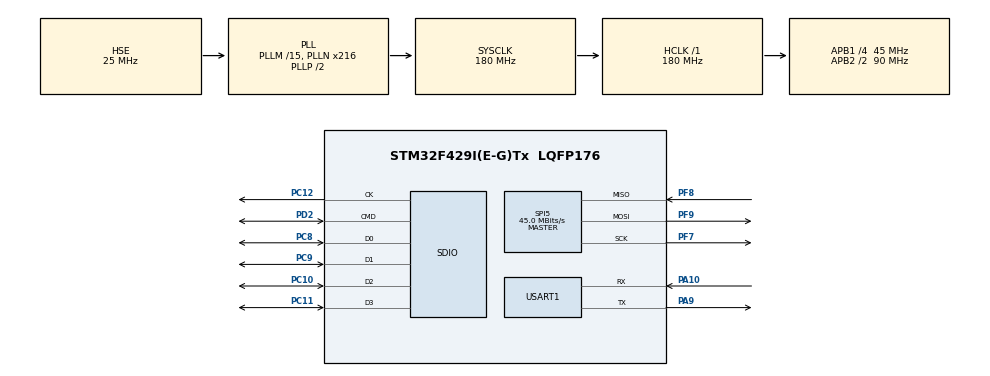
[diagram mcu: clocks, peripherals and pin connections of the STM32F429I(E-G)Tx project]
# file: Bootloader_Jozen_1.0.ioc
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Dma.Request0=SDIO_RX
Dma.Request1=SDIO_TX
Dma.SDIO_RX.0.Direction=DMA_PERIPH_TO_MEMORY
Dma.SDIO_RX.0.FIFOMode=DMA_FIFOMODE_ENABLE
Dma.SDIO_RX.0.FIFOThreshold=DMA_FIFO_THRESHOLD_FULL
Dma.SDIO_RX.0.Instance=DMA2_Stream3
Dma.SDIO_RX.0.MemBurst=DMA_MBURST_INC4
Dma.SDIO_RX.0.MemDataAlignment=DMA_MDATAALIGN_WORD
Dma.SDIO_RX.0.MemInc=DMA_MINC_ENABLE
Dma.SDIO_RX.0.Mode=DMA_PFCTRL
Dma.SDIO_RX.0.PeriphBurst=DMA_PBURST_INC4
Dma.SDIO_RX.0.PeriphDataAlignment=DMA_PDATAALIGN_WORD
Dma.SDIO_RX.0.PeriphInc=DMA_PINC_DISABLE
Dma.SDIO_RX.0.Priority=DMA_PRIORITY_LOW
Dma.SDIO_TX.1.Direction=DMA_MEMORY_TO_PERIPH
Dma.SDIO_TX.1.FIFOMode=DMA_FIFOMODE_ENABLE
Dma.SDIO_TX.1.FIFOThreshold=DMA_FIFO_THRESHOLD_FULL
Dma.SDIO_TX.1.Instance=DMA2_Stream6
Dma.SDIO_TX.1.MemBurst=DMA_MBURST_INC4
Dma.SDIO_TX.1.MemDataAlignment=DMA_MDATAALIGN_WORD
Dma.SDIO_TX.1.MemInc=DMA_MINC_ENABLE
Dma.SDIO_TX.1.Mode=DMA_PFCTRL
Dma.SDIO_TX.1.PeriphBurst=DMA_PBURST_INC4
Dma.SDIO_TX.1.PeriphDataAlignment=DMA_PDATAALIGN_WORD
Dma.SDIO_TX.1.PeriphInc=DMA_PINC_DISABLE
Dma.SDIO_TX.1.Priority=DMA_PRIORITY_LOW
Mcu.Family=STM32F4
Mcu.Name=STM32F429I(E-G)Tx
Mcu.Package=LQFP176
NVIC.DMA2_Stream3_IRQn=true\:0\:0\:false\:false\:true\:false\:true
NVIC.DMA2_Stream6_IRQn=true\:0\:0\:false\:false\:true\:false\:true
NVIC.PriorityGroup=NVIC_PRIORITYGROUP_4
NVIC.SDIO_IRQn=true\:0\:0\:false\:false\:true\:true\:true
NVIC.USART1_IRQn=true\:0\:0\:false\:false\:true\:true\:true
PA10.Mode=Asynchronous
PA10.Signal=USART1_RX
PA13.Mode=Serial_Wire
PA13.Signal=SYS_JTMS-SWDIO
PA14.Mode=Serial_Wire
PA14.Signal=SYS_JTCK-SWCLK
PA9.Mode=Asynchronous
PA9.Signal=USART1_TX
PC10.Mode=SD_4_bits_Wide_bus
PC10.Signal=SDIO_D2
PC11.Mode=SD_4_bits_Wide_bus
PC11.Signal=SDIO_D3
PC12.Mode=SD_4_bits_Wide_bus
PC12.Signal=SDIO_CK
PC8.Mode=SD_4_bits_Wide_bus
PC8.Signal=SDIO_D0
PC9.Mode=SD_4_bits_Wide_bus
PC9.Signal=SDIO_D1
PD2.Mode=SD_4_bits_Wide_bus
PD2.Signal=SDIO_CMD
PF7.Mode=Full_Duplex_Master
PF7.Signal=SPI5_SCK
PF8.Mode=Full_Duplex_Master
PF8.Signal=SPI5_MISO
PF9.Mode=Full_Duplex_Master
PF9.Signal=SPI5_MOSI
PH0/OSC_IN.Mode=HSE-External-Oscillator
PH0/OSC_IN.Signal=RCC_OSC_IN
PH1/OSC_OUT.Mode=HSE-External-Oscillator
PH1/OSC_OUT.Signal=RCC_OSC_OUT
ProjectManager.HeapSize=0x200
ProjectManager.StackSize=0x400
ProjectManager.TargetToolchain=MDK-ARM V5
RCC.48MHZClocksFreq_Value=90000000
RCC.AHBFreq_Value=180000000
RCC.APB1CLKDivider=RCC_HCLK_DIV4
RCC.APB1Freq_Value=45000000
RCC.APB1TimFreq_Value=90000000
RCC.APB2CLKDivider=RCC_HCLK_DIV2
RCC.APB2Freq_Value=90000000
RCC.APB2TimFreq_Value=180000000
RCC.CortexFreq_Value=180000000
RCC.HCLKFreq_Value=180000000
RCC.HSE_VALUE=25000000
RCC.HSI_VALUE=16000000
RCC.LSE_VALUE=32768
RCC.PLLM=15
RCC.PLLN=216
RCC.PLLSourceVirtual=RCC_PLLSOURCE_HSE
RCC.SYSCLKFreq_VALUE=180000000
RCC.SYSCLKSource=RCC_SYSCLKSOURCE_PLLCLK
RCC.VCOOutputFreq_Value=360000000
SPI5.CalculateBaudRate=45.0 MBits/s
SPI5.Direction=SPI_DIRECTION_2LINES
SPI5.Mode=SPI_MODE_MASTER
SPI5.VirtualType=VM_MASTER
USART1.VirtualMode=VM_ASYNC
VP_FATFS_VS_SDIO.Mode=SDIO
board=custom

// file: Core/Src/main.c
/* USER CODE BEGIN Header */
/**
  ******************************************************************************
  * @file           : main.c
  * @brief          : Main program body
  ******************************************************************************
  * @attention
  *
  * <h2><center>&copy; Copyright (c) 2021 STMicroelectronics.
  * All rights reserved.</center></h2>
  *
  * This software component is licensed by ST under BSD 3-Clause license,
  * the "License"; You may not use this file except in compliance with the
  * License. You may obtain a copy of the License at:
  *                        opensource.org/licenses/BSD-3-Clause
  *
  ******************************************************************************
  */
/* USER CODE END Header */
#include "main.h"
#include "dma.h"
#include "fatfs.h"
#include "sdio.h"
#include "spi.h"
#include "usart.h"
#include "gpio.h"

/* USER CODE BEGIN Includes */
#include "interaction.h"
/* USER CODE END Includes */

void SystemClock_Config(void);

int main(void)
{

  /* MCU Configuration--------------------------------------------------------*/

  /* Reset of all peripherals, Initializes the Flash interface and the Systick. */
  HAL_Init();

  /* Configure the system clock */
  SystemClock_Config();

  /* Initialize all configured peripherals */
  MX_GPIO_Init();
  MX_DMA_Init();
  MX_USART1_UART_Init();
  MX_SDIO_SD_Init();
  MX_FATFS_Init();
  MX_SPI5_Init();
  /* USER CODE BEGIN 2 */
	Interaction();
  /* USER CODE END 2 */

  /* Infinite loop */
  while (1)
  {

  }
}

void SystemClock_Config(void)
{
  RCC_OscInitTypeDef RCC_OscInitStruct = {0};
  RCC_ClkInitTypeDef RCC_ClkInitStruct = {0};

  /** Configure the main internal regulator output voltage
  */
  __HAL_RCC_PWR_CLK_ENABLE();
  __HAL_PWR_VOLTAGESCALING_CONFIG(PWR_REGULATOR_VOLTAGE_SCALE1);
  /** Initializes the RCC Oscillators according to the specified parameters
  * in the RCC_OscInitTypeDef structure.
  */
  RCC_OscInitStruct.OscillatorType = RCC_OSCILLATORTYPE_HSE;
  RCC_OscInitStruct.HSEState = RCC_HSE_ON;
  RCC_OscInitStruct.PLL.PLLState = RCC_PLL_ON;
  RCC_OscInitStruct.PLL.PLLSource = RCC_PLLSOURCE_HSE;
  RCC_OscInitStruct.PLL.PLLM = 15;
  RCC_OscInitStruct.PLL.PLLN = 216;
  RCC_OscInitStruct.PLL.PLLP = RCC_PLLP_DIV2;
  RCC_OscInitStruct.PLL.PLLQ = 4;
  if (HAL_RCC_OscConfig(&RCC_OscInitStruct) != HAL_OK)
  {
    Error_Handler();
  }
  /** Activate the Over-Drive mode
  */
  if (HAL_PWREx_EnableOverDrive() != HAL_OK)
  {
    Error_Handler();
  }
  /** Initializes the CPU, AHB and APB buses clocks
  */
  RCC_ClkInitStruct.ClockType = RCC_CLOCKTYPE_HCLK|RCC_CLOCKTYPE_SYSCLK
                              |RCC_CLOCKTYPE_PCLK1|RCC_CLOCKTYPE_PCLK2;
  RCC_ClkInitStruct.SYSCLKSource = RCC_SYSCLKSOURCE_PLLCLK;
  RCC_ClkInitStruct.AHBCLKDivider = RCC_SYSCLK_DIV1;
  RCC_ClkInitStruct.APB1CLKDivider = RCC_HCLK_DIV4;
  RCC_ClkInitStruct.APB2CLKDivider = RCC_HCLK_DIV2;

  if (HAL_RCC_ClockConfig(&RCC_ClkInitStruct, FLASH_LATENCY_5) != HAL_OK)
  {
    Error_Handler();
  }
}

void Error_Handler(void)
{
}

/************************ (C) COPYRIGHT STMicroelectronics *****END OF FILE****/
